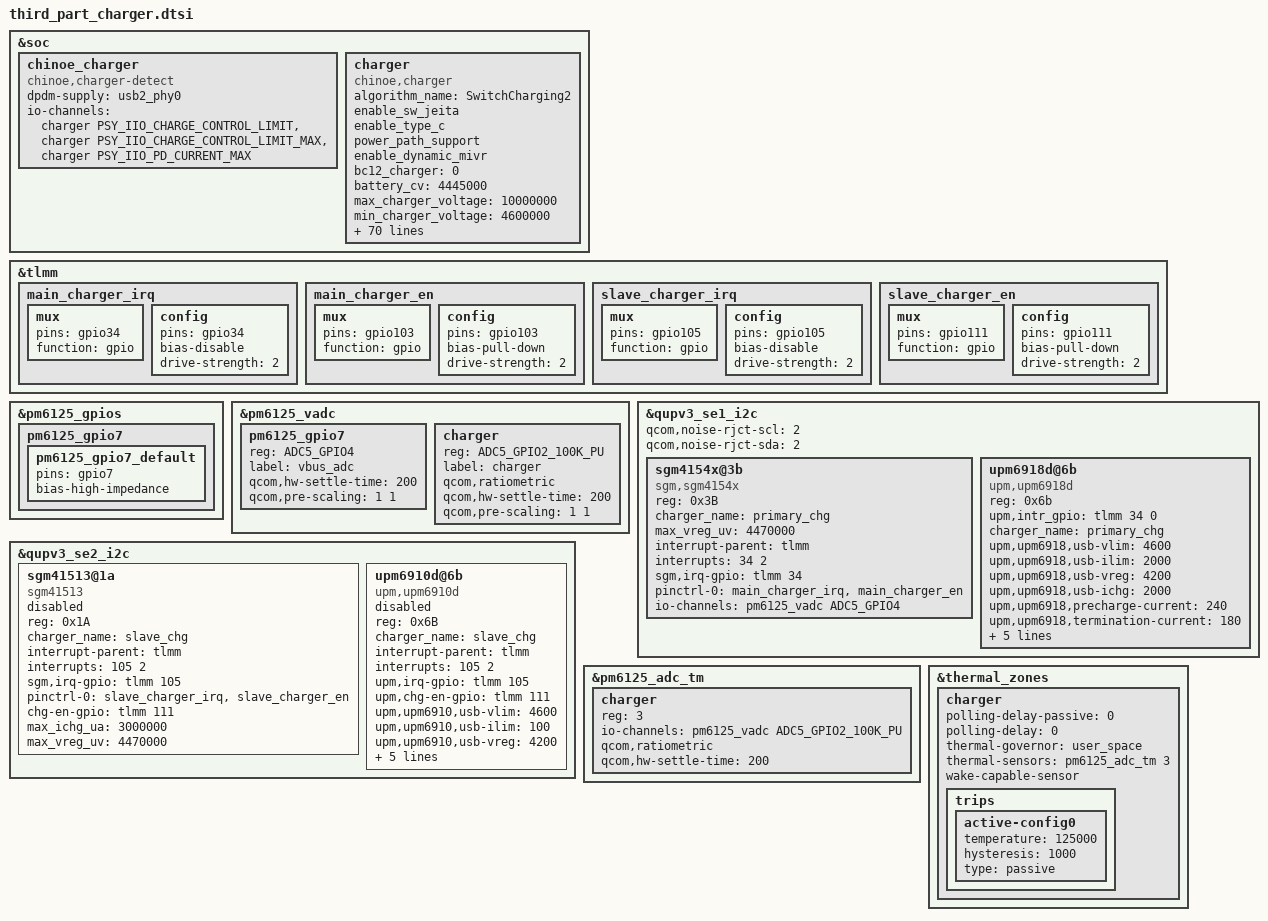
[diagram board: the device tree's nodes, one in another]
/*
 * Copyright (C) 2018 Chino-e Inc.
 *
 * This program is free software; you can redistribute it and/or modify
 * it under the terms of the GNU General Public License version 2 as
 * published by the Free Software Foundation.
 *
 * This program is distributed in the hope that it will be useful,
 * but WITHOUT ANY WARRANTY; without even the implied warranty of
 * MERCHANTABILITY or FITNESS FOR A PARTICULAR PURPOSE.
 * See http://www.gnu.org/licenses/gpl-2.0.html for more details.
 */

#include <dt-bindings/iio/qti_power_supply_iio.h>
#include <dt-bindings/iio/qcom,spmi-vadc.h>

&soc {
	chinoe_charger: chinoe_charger {
		compatible = "chinoe,charger-detect";
		dpdm-supply = <&usb2_phy0>;

		#io-channel-cells = <1>;
		io-channels = <&charger PSY_IIO_CHARGE_CONTROL_LIMIT>,
		              <&charger PSY_IIO_CHARGE_CONTROL_LIMIT_MAX>,
		              <&charger PSY_IIO_PD_CURRENT_MAX>;
		io-channel-names = "charge_control_limit",
		                   "charge_control_limit_max",
		                   "current_max";
	};

	charger: charger {
		compatible = "chinoe,charger";
		algorithm_name = "SwitchCharging2";
		enable_sw_jeita;
		enable_type_c;
		power_path_support;
		enable_dynamic_mivr;

		bc12_charger = <0>;

		/* common */
		battery_cv = <4445000>;
		max_charger_voltage = <10000000>;
		min_charger_voltage = <4600000>;
		enable_software_control_recharge;
		recharge_voltage_threshold = <70000>;  /* 70mV */

		hvdcp_charger_input_current = <2000000>;
		hvdcp_charger_current = <3500000>;
		hvdcp_polling_interval = <5>;

		/* dynamic mivr */
		min_charger_voltage_1 = <4600000>;
		min_charger_voltage_2 = <4500000>;
		max_dmivr_charger_current = <1400000>;

		/* charging current */
		usb_charger_current_suspend = <0>;
		usb_charger_current_unconfigured = <70000>;
		usb_charger_current_configured = <500000>;
		usb_charger_current = <500000>;
		ac_charger_current = <2500000>;
		ac_charger_input_current = <2000000>;
		non_std_ac_charger_current = <500000>;
		charging_host_charger_current = <1500000>;
		apple_1_0a_charger_current = <650000>;
		apple_2_1a_charger_current = <800000>;
		ta_ac_charger_current = <3000000>;

		/* hvdcp */
		hvdcp_exit_soc = <90>;
		hvdcp_exit_curr_ma = <1000>;
		hvdcp_exit_temp_h = <150>;
		hvdcp_exit_temp_l = <450>;

		/* sw jeita */
		/* t0:0 t1:10 t2:15 t3:45 t4:55 */
		jeita_temp_above_t4_cv = <4100000>;
		jeita_temp_t3_to_t4_cv = <4100000>;
		jeita_temp_t2_to_t3_cv = <4445000>;
		jeita_temp_t1_to_t2_cv = <4445000>;
		jeita_temp_t0_to_t1_cv = <4445000>;
		jeita_temp_below_t0_cv = <4445000>;
		jeita_temp_above_t4_cur = <0>;
		jeita_temp_t3_to_t4_cur = <2000000>;
		jeita_temp_t2_to_t3_cur = <3600000>;
		jeita_temp_t1_to_t2_cur = <800000>;
		jeita_temp_t0_to_t1_cur = <800000>;
		jeita_temp_below_t0_cur = <0>;
		temp_t4_thres = <550>;
		temp_t4_thres_minus_x_degree = <530>;
		temp_t3_thres = <450>;
		temp_t3_thres_minus_x_degree = <430>;
		temp_t2_thres = <150>;
		temp_t2_thres_plus_x_degree = <190>;
		temp_t1_thres = <100>;
		temp_t1_thres_plus_x_degree = <120>;
		temp_t0_thres = <10>;
		temp_t0_thres_plus_x_degree = <30>;

		/* battery temperature protection */
		enable_min_charge_temp;
		min_charge_temp = <0>;
		min_charge_temp_plus_x_degree = <20>;
		max_charge_temp = <550>;
		max_charge_temp_minus_x_degree = <530>;

		/* dual charger */
		chg1_ta_ac_charger_current = <1500000>;
		chg2_ta_ac_charger_current = <1500000>;
		slave_mivr_diff = <100000>;
		dual_polling_ieoc = <750000>;

		/* cable measurement impedance */
		cable_imp_threshold = <699>;
		vbat_cable_imp_threshold = <3900000>; /* uV */

		/* bif */
		bif_threshold1 = <4250000>;
		bif_threshold2 = <4300000>;
		bif_cv_under_threshold2 = <4445000>;

		/* PD */
		pd_charger_current = <3500000>;
		pd_charger_input_current = <2000000>;
		pd_vbus_low_bound = <5000000>;
		pd_vbus_upper_bound = <10000000>;
		pd_ichg_level_threshold = <1000000>; /* uA */
		pd_stop_battery_soc = <90>;

		ibus_err = <14>;
		vsys_watt = <5000000>;

		#io-channel-cells = <1>;

		thermal-mitigation = <3500000 3000000 2500000 2000000 1500000
				1000000 800000 600000 200000 0>;

		time-param = <600 3000000>;
	};

//	pd_adapter: pd_adapter {
//		compatible = "chinoe,pd_adapter";
//		adapter_name = "pd_adapter";
//	};
};

&tlmm {
	main_charger_irq: main_charger_irq {
		mux {
			pins = "gpio34";
			function = "gpio";
		};
	
		config {
			pins = "gpio34";
			bias-disable; /* No PULL */
			drive-strength = <2>;
		};
	};

	main_charger_en: main_charger_en {
		mux {
			pins = "gpio103";
			function = "gpio";
		};
	
		config {
			pins = "gpio103";
			bias-pull-down;
			drive-strength = <2>;
		};
	};

	slave_charger_irq: slave_charger_irq {
		mux {
			pins = "gpio105";
			function = "gpio";
		};
	
		config {
			pins = "gpio105";
			bias-disable; /* No PULL */
			drive-strength = <2>;
		};
	};

	slave_charger_en: slave_charger_en {
		mux {
			pins = "gpio111";
			function = "gpio";
		};
	
		config {
			pins = "gpio111";
			bias-pull-down;
			drive-strength = <2>;
		};
	};
};

&pm6125_gpios {
	pm6125_gpio7 {
		pm6125_gpio7_default: pm6125_gpio7_default {
			pins = "gpio7";
			bias-high-impedance;
		};
	};
};

&pm6125_vadc {
	pm6125_gpio7 {
		reg = <ADC5_GPIO4>;
		label = "vbus_adc";
		qcom,hw-settle-time = <200>;
		qcom,pre-scaling = <1 1>;
	};
};

&qupv3_se1_i2c {
	status = "okay";
	/* bug APOLLO-963, chenyu, 20220523, begin */
	qcom,noise-rjct-scl = <2>;
	qcom,noise-rjct-sda = <2>;
	/* bug APOLLO-963, chenyu, 20220523, end */
	sgm4154x@3b {
		status = "okay";
		compatible = "sgm,sgm4154x";
		reg = <0x3B>;

		charger_name = "primary_chg";
		max_vreg_uv = <4470000>;
		interrupt-parent = <&tlmm>;
		interrupts = <34 2>;
		sgm,irq-gpio = <&tlmm 34 0>;

		pinctrl-names = "main_1st_config";
		pinctrl-0 = <&main_charger_irq>, <&main_charger_en>;
		io-channels = <&pm6125_vadc ADC5_GPIO4>;
		io-channel-names = "vbus_adc";
	};

	upm6918d@6b {
		compatible = "upm,upm6918d";
		reg = <0x6b>;
		upm,intr_gpio = <&tlmm 34 0>;

		charger_name = "primary_chg";
		upm,upm6918,usb-vlim = <4600>;
		upm,upm6918,usb-ilim = <2000>;
		upm,upm6918,usb-vreg = <4200>;
		upm,upm6918,usb-ichg = <2000>;
		upm,upm6918,precharge-current = <240>;
		upm,upm6918,termination-current = <180>;
		upm,upm6918,boost-voltage = <5000>;
		upm,upm6918,boost-current = <1200>;
		upm,upm6918,vac-ovp-threshold = <10500>;
		pinctrl-names = "main_2nd_config";
		pinctrl-0 = <&main_charger_irq>, <&main_charger_en>;
		io-channels = <&pm6125_vadc ADC5_GPIO4>;
		io-channel-names = "vbus_adc";
	};
};

&qupv3_se2_i2c {
	status = "ok";
	sgm41513@1a {
		status = "disabled";
		compatible = "sgm41513";
		reg = <0x1A>;

		charger_name = "slave_chg";
		interrupt-parent = <&tlmm>;
		interrupts = <105 2>;
		sgm,irq-gpio = <&tlmm 105 0>;

		pinctrl-names = "slave_1st_config";
		pinctrl-0 = <&slave_charger_irq>, <&slave_charger_en>;

		chg-en-gpio = <&tlmm 111 0>;
		max_ichg_ua = <3000000>;
		max_vreg_uv = <4470000>;
	};

	upm6910d@6b {
		status = "disabled";
		compatible = "upm,upm6910d";
		reg = <0x6B>;

		charger_name = "slave_chg";
		interrupt-parent = <&tlmm>;
		interrupts = <105 2>;
		upm,irq-gpio = <&tlmm 105 0>;
		upm,chg-en-gpio = <&tlmm 111 0>;
		upm,upm6910,usb-vlim = <4600>;
		upm,upm6910,usb-ilim = <100>;
		upm,upm6910,usb-vreg = <4200>;
		upm,upm6910,usb-ichg = <60>;
		upm,upm6910,precharge-current = <240>;
		upm,upm6910,termination-current = <180>;
		upm,upm6910,vac-ovp-threshold = <10500>;
		pinctrl-names = "slave_2nd_config";
		pinctrl-0 = <&slave_charger_irq>, <&slave_charger_en>;
	};
};

&pm6125_vadc {
	charger {
		reg = <ADC5_GPIO2_100K_PU>;
		label = "charger";
		qcom,ratiometric;
		qcom,hw-settle-time = <200>;
		qcom,pre-scaling = <1 1>;
	};
};

&pm6125_adc_tm {
	charger {
		reg = <3>;
		io-channels = <&pm6125_vadc ADC5_GPIO2_100K_PU>;
		qcom,ratiometric;
		qcom,hw-settle-time = <200>;
	};
};

&thermal_zones {
	charger {
		polling-delay-passive = <0>;
		polling-delay = <0>;
		thermal-governor = "user_space";
		thermal-sensors = <&pm6125_adc_tm 3>;
		wake-capable-sensor;
		trips {
			active-config0 {
				temperature = <125000>;
				hysteresis = <1000>;
				type = "passive";
			};
		};
	};
};
